# GD32F50x register map
File version: 1.0
CPU: CM33 r2p1, little endian, MPU, FPU, 4 interrupt priority bits
Registers are 32-bit, read-write, reset 0x0 unless marked. A register's access mark holds for its fields unless they carry their own. Offsets are from the block's base; [hi:lo] are bit positions; {n}, {i} and the like mark numbered series.

## RCU — Reset and clock unit
Base 0x40021000
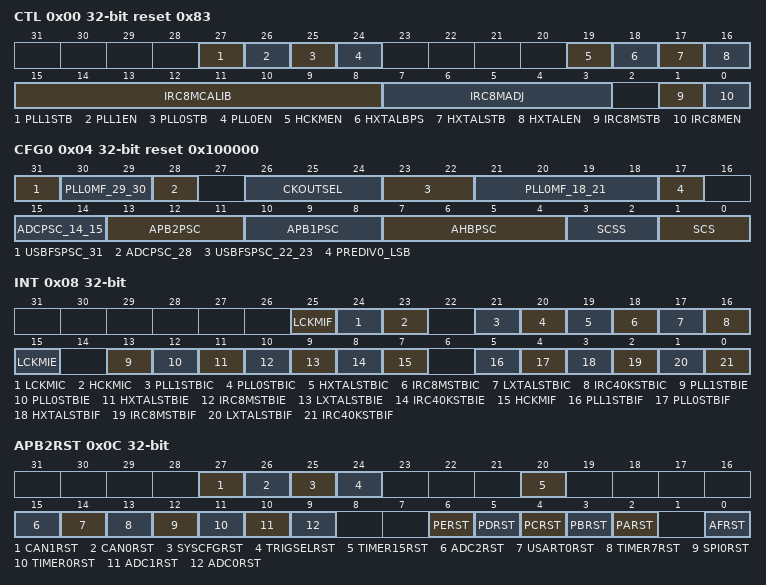
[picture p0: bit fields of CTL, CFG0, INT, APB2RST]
0x00 CTL access per field reset 0x83 — Control register
  [27] PLL1STB ro — PLL1 clock stabilization flag
  [26] PLL1EN rw — PLL1 enable
  [25] PLL0STB ro — PLL0 clock stabilization flag
  [24] PLL0EN rw — PLL0 enable
  [19] HCKMEN rw — HXTAL clock monitor enable
  [18] HXTALBPS rw — High speed crystal oscillator (HXTAL) clock bypass mode enable
  [17] HXTALSTB ro — High speed crystal oscillator (HXTAL) clock stabilization flag
  [16] HXTALEN rw — High speed crystal oscillator (HXTAL) Enable
  [15:8] IRC8MCALIB ro — Internal 8MHz RC oscillator calibration value register
  [7:3] IRC8MADJ rw — Internal 8MHz RC oscillator clock trim adjust value
  [1] IRC8MSTB ro — IRC8M internal 8MHz RC oscillator stabilization flag
  [0] IRC8MEN rw — Internal 8MHz RC oscillator enable
0x04 CFG0 access per field reset 0x100000 — Clock configuration register 0
  [31] USBFSPSC_31 rw — Bit 2 of USBFSPSC
  [30:29] PLL0MF_29_30 rw — Bit 5 and Bit 4 of PLL0MF
  [28] ADCPSC_28 rw — Bit 2 of ADCPSC
  [26:24] CKOUTSEL rw — CKOUT clock source selection
  [23:22] USBFSPSC_22_23 rw — USBFS clock prescaler selection
  [21:18] PLL0MF_18_21 rw — The PLL0 clock multiplication factor
  [17] PREDIV0_LSB rw — The LSB of PREDIV0 division factor
  [15:14] ADCPSC_14_15 rw — ADC clock prescaler selection
  [13:11] APB2PSC rw — APB2 prescaler selection
  [10:8] APB1PSC rw — APB1 prescaler selection
  [7:4] AHBPSC rw — AHB prescaler selection
  [3:2] SCSS ro — System clock switch status
  [1:0] SCS rw — System clock switch
0x08 INT access per field — Clock interrupt register
  [25] LCKMIF ro — LXTAL clock stuck interrupt flag
  [24] LCKMIC wo — LXTAL clock stuck interrupt clear
  [23] HCKMIC wo — HXTAL clock stuck interrupt clear
  [21] PLL1STBIC wo — PLL1 stabilization interrupt clear
  [20] PLL0STBIC wo — PLL0 stabilization interrupt clear
  [19] HXTALSTBIC wo — HXTAL stabilization interrupt clear
  [18] IRC8MSTBIC wo — IRC8M stabilization interrupt clear
  [17] LXTALSTBIC wo — LXTAL stabilization interrupt clear
  [16] IRC40KSTBIC wo — IRC40K stabilization interrupt clear
  [15] LCKMIE rw — LXTAL clock stuck interrupt enable
  [13] PLL1STBIE rw — PLL1 stabilization interrupt enable
  [12] PLL0STBIE rw — PLL0 stabilization interrupt enable
  [11] HXTALSTBIE rw — HXTAL stabilization interrupt enable
  [10] IRC8MSTBIE rw — IRC8M stabilization interrupt enable
  [9] LXTALSTBIE rw — LXTAL stabilization interrupt enable
  [8] IRC40KSTBIE rw — IRC40K stabilization interrupt enable
  [7] HCKMIF ro — HXTAL clock stuck interrupt flag
  [5] PLL1STBIF ro — PLL1 stabilization interrupt flag
  [4] PLL0STBIF ro — PLL0 stabilization interrupt flag
  [3] HXTALSTBIF ro — HXTAL stabilization interrupt flag
  [2] IRC8MSTBIF ro — IRC8M stabilization interrupt flag
  [1] LXTALSTBIF ro — LXTAL stabilization interrupt flag
  [0] IRC40KSTBIF ro — IRC40K stabilization interrupt flag
0x0C APB2RST — APB2 reset register
  [27] CAN1RST — CAN1 reset
  [26] CAN0RST — CAN0 reset
  [25] SYSCFGRST — SYSCFG reset
  [24] TRIGSELRST — TRIGSEL reset
  [20] TIMER15RST — TIMER15 reset
  [15] ADC2RST — ADC2 reset
  [14] USART0RST — USART0 reset
  [13] TIMER7RST — Timer 7 reset
  [12] SPI0RST — SPI0 reset
  [11] TIMER0RST — Timer 0 reset
  [10] ADC1RST — ADC1 reset
  [9] ADC0RST — ADC0 reset
  [6] PERST — GPIO port E reset
  [5] PDRST — GPIO port D reset
  [4] PCRST — GPIO port C reset
  [3] PBRST — GPIO port B reset
  [2] PARST — GPIO port A reset
  [0] AFRST — Alternate function I/O reset
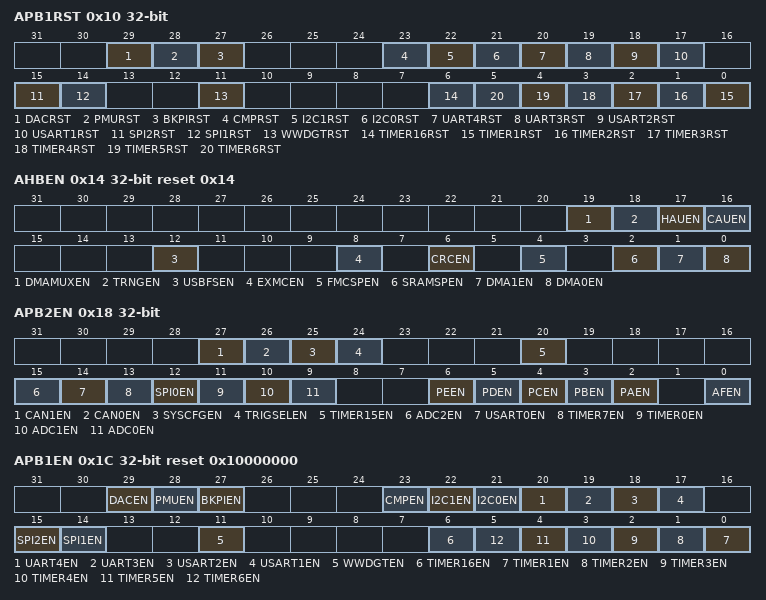
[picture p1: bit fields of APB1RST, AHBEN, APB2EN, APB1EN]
0x10 APB1RST — APB1 reset register
  [29] DACRST — DAC reset
  [28] PMURST — Power control reset
  [27] BKPIRST — Backup interface reset
  [23] CMPRST — CMP interface reset
  [22] I2C1RST — I2C1 reset
  [21] I2C0RST — I2C0 reset
  [20] UART4RST — UART4 reset
  [19] UART3RST — UART3 reset
  [18] USART2RST — USART2 reset
  [17] USART1RST — USART1 reset
  [15] SPI2RST — SPI2 reset
  [14] SPI1RST — SPI1 reset
  [11] WWDGTRST — WWDGT reset
  [6] TIMER16RST — TIMER16 reset
  [n-1] TIMER{n}RST (n=1..6) — TIMER{n} reset
0x14 AHBEN reset 0x14 — AHB enable register
  [19] DMAMUXEN — DMAMUX clock enable
  [18] TRNGEN — TRNG clock enable
  [17] HAUEN — HAU clock enable
  [16] CAUEN — CAU clock enable
  [12] USBFSEN — USBFS clock enable
  [8] EXMCEN — EXMC clock enable
  [6] CRCEN — CRC clock enable
  [4] FMCSPEN — FMC clock enable when sleep mode
  [2] SRAMSPEN — SRAM interface clock enable when sleep mode
  [1] DMA1EN — DMA1 clock enable
  [0] DMA0EN — DMA0 clock enable
0x18 APB2EN — APB2 enable register
  [27] CAN1EN — CAN1 clock enable
  [26] CAN0EN — CAN0 clock enable
  [25] SYSCFGEN — SYSCFG clock enable
  [24] TRIGSELEN — TRIGSEL clock enable
  [20] TIMER15EN — TIMER15 clock enable
  [15] ADC2EN — ADC2 clock enable
  [14] USART0EN — USART0 clock enable
  [13] TIMER7EN — TIMER7 clock enable
  [12] SPI0EN — SPI0 clock enable
  [11] TIMER0EN — TIMER0 clock enable
  [10] ADC1EN — ADC1 clock enable
  [9] ADC0EN — ADC0 clock enable
  [6] PEEN — GPIO port E clock enable
  [5] PDEN — GPIO port D clock enable
  [4] PCEN — GPIO port C clock enable
  [3] PBEN — GPIO port B clock enable
  [2] PAEN — GPIO port A clock enable
  [0] AFEN — Alternate function IO clock enable
0x1C APB1EN reset 0x10000000 — APB1 enable register
  [29] DACEN — DAC clock enable
  [28] PMUEN — PMU clock enable
  [27] BKPIEN — Backup interface clock enable
  [23] CMPEN — CMP clock enable
  [22] I2C1EN — I2C1 clock enable
  [21] I2C0EN — I2C0 clock enable
  [20] UART4EN — UART4 clock enable
  [19] UART3EN — UART3 clock enable
  [18] USART2EN — USART2 clock enable
  [17] USART1EN — USART1 clock enable
  [15] SPI2EN — SPI2 clock enable
  [14] SPI1EN — SPI1 clock enable
  [11] WWDGTEN — WWDGT clock enable
  [6] TIMER16EN — TIMER16 clock enable
  [n-1] TIMER{n}EN (n=1..6) — TIMER{n} clock enable
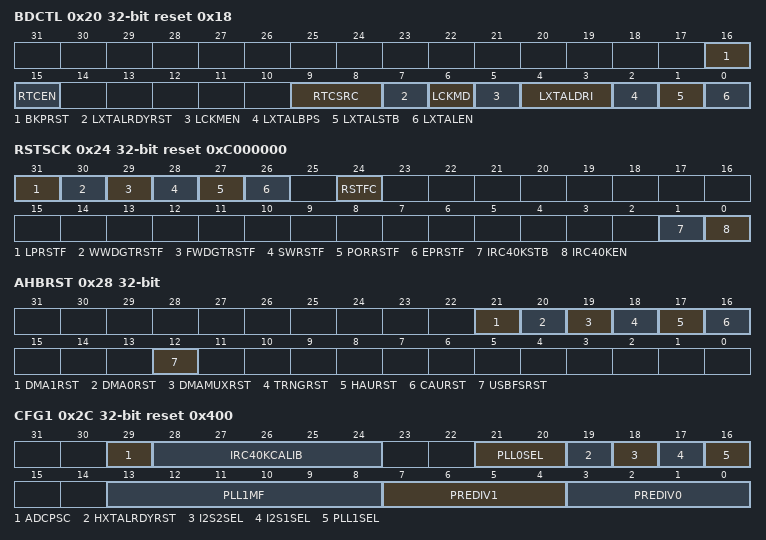
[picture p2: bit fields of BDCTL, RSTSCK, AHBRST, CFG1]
0x20 BDCTL access per field reset 0x18 — Backup domain control register
  [16] BKPRST rw — Backup domain reset
  [15] RTCEN rw — RTC clock enable
  [9:8] RTCSRC rw — RTC clock entry selection
  [7] LXTALRDYRST wo — LXTAL ready reset
  [6] LCKMD ro — LXTAL clock failure detection
  [5] LCKMEN rw — LXTAL clock monitor enable
  [4:3] LXTALDRI rw — LXTAL drive capability
  [2] LXTALBPS rw — LXTAL bypass mode enable
  [1] LXTALSTB ro — Low speed crystal oscillator stabilization flag
  [0] LXTALEN rw — LXTAL enable
0x24 RSTSCK access per field reset 0xC000000 — Reset source/clock register
  [31] LPRSTF ro — Low-power reset flag
  [30] WWDGTRSTF ro — Window watchdog timer reset flag
  [29] FWDGTRSTF ro — Free watchdog timer reset flag
  [28] SWRSTF ro — Software reset flag
  [27] PORRSTF ro — Power reset flag
  [26] EPRSTF ro — External pin reset flag
  [24] RSTFC rw — Reset flag clear
  [1] IRC40KSTB ro — IRC40K stabilization flag
  [0] IRC40KEN rw — IRC40K enable
0x28 AHBRST — AHB reset register
  [21] DMA1RST — DMA0 reset
  [20] DMA0RST — DMA1 reset
  [19] DMAMUXRST — DMAMUX reset
  [18] TRNGRST — TRNG reset
  [17] HAURST — HAU reset
  [16] CAURST — CAU reset
  [12] USBFSRST — USBFS reset
0x2C CFG1 access per field reset 0x400 — Clock configuration register 1
  [29] ADCPSC rw — Bit 4 of ADCPSC
  [28:24] IRC40KCALIB ro — Internal 40KHz RC oscillator calibration value register
  [21:20] PLL0SEL rw — PLL0 clock source selection
  [19] HXTALRDYRST rw — HXTAL ready reset
  [18] I2S2SEL rw — I2S2 Clock Source Selection
  [17] I2S1SEL rw — I2S1 Clock Source Selection
  [16] PLL1SEL rw — PLL1 clock source selection
  [13:8] PLL1MF rw — The PLL1 clock multiplication factor
  [7:4] PREDIV1 rw — PREDIV1 division factor
  [3:0] PREDIV0 rw — PREDIV0 division factor
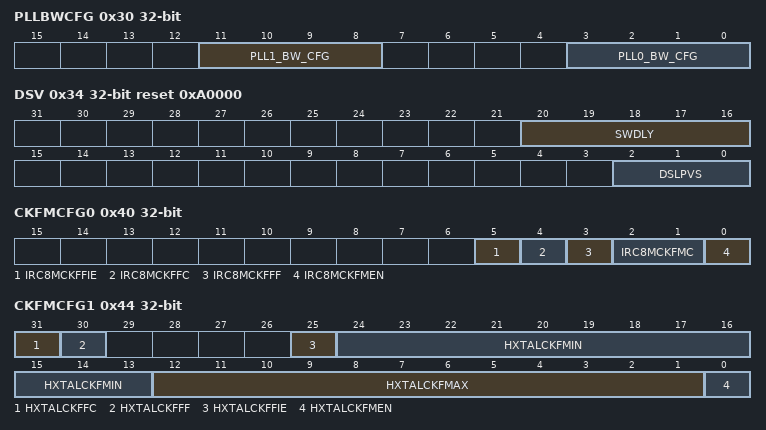
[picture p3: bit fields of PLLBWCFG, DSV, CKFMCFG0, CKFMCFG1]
0x30 PLLBWCFG — PLL bandwidth configuration register
  [11:8] PLL1_BW_CFG — PLL1 bandwidth configuration
  [3:0] PLL0_BW_CFG — PLL0 bandwidth configuration
0x34 DSV reset 0xA0000 — Deep-sleep mode voltage register
  [20:16] SWDLY — switch delay time
  [2:0] DSLPVS — Deep-sleep mode voltage select
0x40 CKFMCFG0 access per field — Clock frequency monitor configuration register 0
  [5] IRC8MCKFFIE rw — IRC8M clock frequency failure interrupt enable
  [4] IRC8MCKFFC rw — IRC8M clock frequency failure flag clear
  [3] IRC8MCKFFF ro — IRC8M clock frequency failure flag
  [2:1] IRC8MCKFMC rw — IRC8M clock frequency monitor configuration
  [0] IRC8MCKFMEN rw — IRC8M clock frequency monitor enable
0x44 CKFMCFG1 access per field — Clock frequency monitor configuration register 1
  [31] HXTALCKFFC rw — HXTAL clock frequency failure flag clear
  [30] HXTALCKFFF ro — HXTAL clock frequency failure flag
  [25] HXTALCKFFIE rw — HXTAL clock frequency failure interrupt enable
  [24:13] HXTALCKFMIN rw — HXTAL clock frequency monitor configuration minimum value
  [12:1] HXTALCKFMAX rw — HXTAL clock frequency monitor configuration maximum value
  [0] HXTALCKFMEN rw — HXTAL clock frequency monitor enable
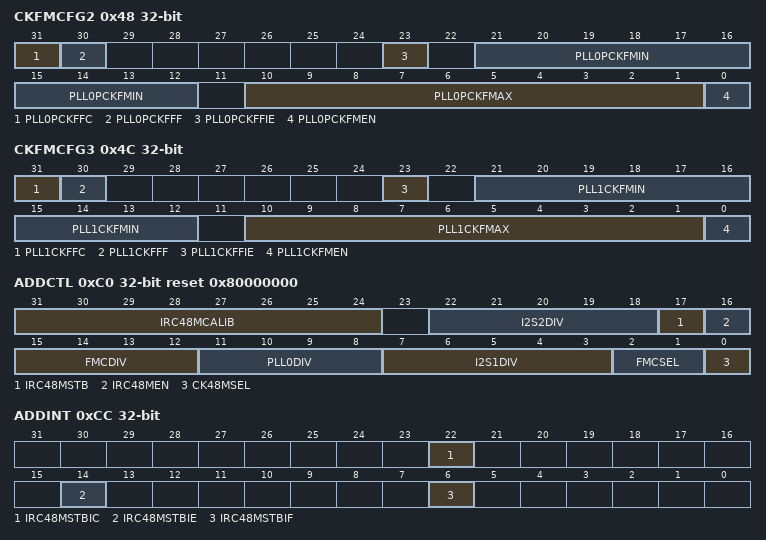
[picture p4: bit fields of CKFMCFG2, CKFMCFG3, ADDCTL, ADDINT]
0x48 CKFMCFG2 access per field — Clock frequency monitor configuration register 2
  [31] PLL0PCKFFC rw — PLL0P clock frequency failure flag clear
  [30] PLL0PCKFFF ro — PLL0P clock frequency failure flag
  [23] PLL0PCKFFIE rw — PLL0P clock frequency failure interrupt enable
  [21:12] PLL0PCKFMIN rw — PLL0P clock frequency monitor configuration minimum value
  [10:1] PLL0PCKFMAX rw — PLL0P clock frequency monitor configuration maximum value
  [0] PLL0PCKFMEN rw — PLL0P clock frequency monitor enable
0x4C CKFMCFG3 access per field — Clock frequency monitor configuration register 3
  [31] PLL1CKFFC rw — PLL1 clock frequency failure flag clear
  [30] PLL1CKFFF ro — PLL1 clock frequency failure flag
  [23] PLL1CKFFIE rw — PLL1 clock frequency failure interrupt enable
  [21:12] PLL1CKFMIN rw — PLL1 clock frequency monitor configuration minimum value
  [10:1] PLL1CKFMAX rw — PLL1 clock frequency monitor configuration maximum value
  [0] PLL1CKFMEN rw — PLL1 clock frequency monitor enable
0xC0 ADDCTL access per field reset 0x80000000 — Additional clock control register
  [31:24] IRC48MCALIB ro — Internal 48MHz RC oscillator calibration value register
  [22:18] I2S2DIV rw — I2S2 divider
  [17] IRC48MSTB ro — Internal 48MHz RC oscillator clock stabilization flag
  [16] IRC48MEN rw — Internal 48MHz RC oscillator enable
  [15:12] FMCDIV rw — FMC divider
  [11:8] PLL0DIV rw — PLL0 divider
  [7:3] I2S1DIV rw — I2S1 divider
  [2:1] FMCSEL rw — FMC clock source selection
  [0] CK48MSEL rw — 48MHz clock selection
0xCC ADDINT access per field — Additional clock interrupt register
  [22] IRC48MSTBIC wo — Internal 48 MHz RC oscillator stabilization interrupt clear
  [14] IRC48MSTBIE rw — Internal 48 MHz RC oscillator stabilization interrupt enable
  [6] IRC48MSTBIF ro — IRC48M stabilization interrupt flag
0xE0 ADDAPB1RST — APB1 additional reset register
  [27] CTCRST — CTC reset
0xE4 ADDAPB1EN — APB1 additional enable register
  [27] CTCEN — CTC clock enable
0x100 LOCK
  [31] LOCK — RCU register lock bit
